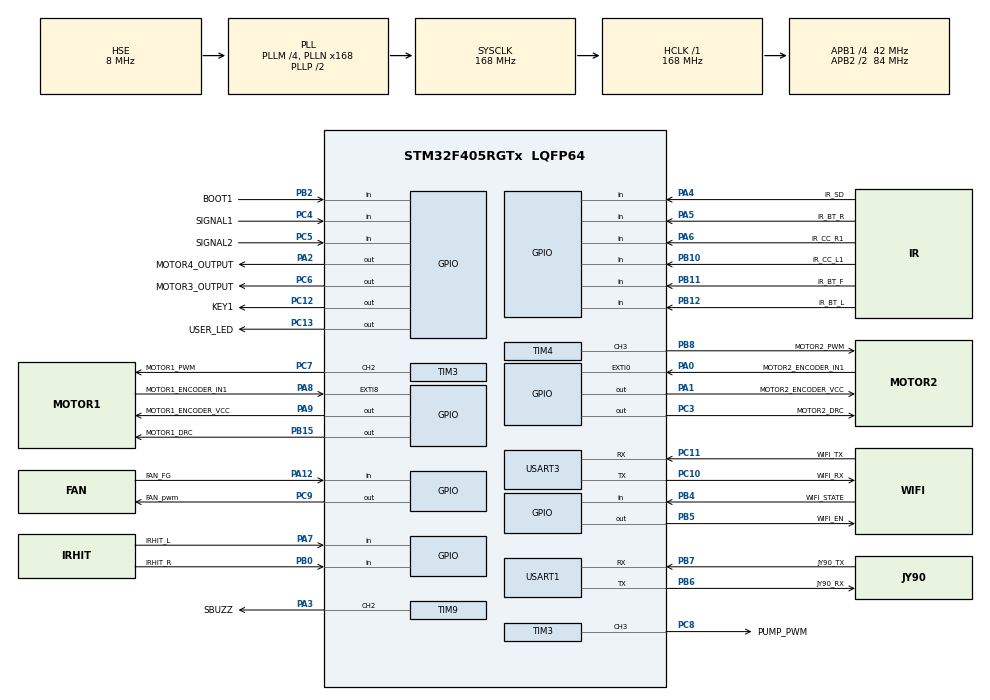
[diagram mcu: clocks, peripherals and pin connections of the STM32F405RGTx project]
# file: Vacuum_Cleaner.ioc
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FREERTOS.Tasks01=defaultTask,24,128,StartDefaultTask,Default,NULL,Dynamic,NULL,NULL
Mcu.Family=STM32F4
Mcu.Name=STM32F405RGTx
Mcu.Package=LQFP64
NVIC.EXTI0_IRQn=true\:5\:0\:false\:false\:true\:true\:true\:true\:true
NVIC.EXTI9_5_IRQn=true\:5\:0\:false\:false\:true\:true\:true\:true\:true
NVIC.PriorityGroup=NVIC_PRIORITYGROUP_4
NVIC.TIM1_UP_TIM10_IRQn=true\:5\:0\:false\:false\:true\:true\:true\:true\:true
NVIC.TIM2_IRQn=true\:5\:0\:false\:false\:true\:true\:true\:true\:true
NVIC.TIM5_IRQn=true\:15\:0\:false\:false\:true\:false\:false\:true\:true
NVIC.TimeBase=TIM5_IRQn
NVIC.TimeBaseIP=TIM5
NVIC.USART1_IRQn=true\:5\:0\:false\:false\:true\:true\:true\:true\:true
NVIC.USART3_IRQn=true\:5\:0\:false\:false\:true\:true\:true\:true\:true
PA0-WKUP.GPIO_Label=MOTOR2_ENCODER_IN1
PA0-WKUP.GPIO_PuPd=GPIO_PULLDOWN
PA0-WKUP.Signal=GPXTI0
PA1.GPIO_Label=MOTOR2_ENCODER_VCC
PA1.PinState=GPIO_PIN_SET
PA1.Signal=GPIO_Output
PA12.GPIO_Label=FAN_FG
PA12.Signal=GPIO_Input
PA13.Mode=Serial_Wire
PA13.Signal=SYS_JTMS-SWDIO
PA14.Mode=Serial_Wire
PA14.Signal=SYS_JTCK-SWCLK
PA2.GPIO_Label=MOTOR4_OUTPUT
PA2.PinState=GPIO_PIN_SET
PA2.Signal=GPIO_Output
PA3.GPIO_Label=SBUZZ
PA3.Signal=S_TIM9_CH2
PA4.GPIO_Label=IR_SD
PA4.Signal=GPIO_Input
PA5.GPIO_Label=IR_BT_R
PA5.Signal=GPIO_Input
PA6.GPIO_Label=IR_CC_R1
PA6.Signal=GPIO_Input
PA7.GPIO_Label=IRHIT_L
PA7.Signal=GPIO_Input
PA8.GPIO_Label=MOTOR1_ENCODER_IN1
PA8.GPIO_PuPd=GPIO_PULLDOWN
PA8.Signal=GPXTI8
PA9.GPIO_Label=MOTOR1_ENCODER_VCC
PA9.PinState=GPIO_PIN_SET
PA9.Signal=GPIO_Output
PB0.GPIO_Label=IRHIT_R
PB0.Signal=GPIO_Input
PB10.GPIO_Label=IR_CC_L1
PB10.Signal=GPIO_Input
PB11.GPIO_Label=IR_BT_F
PB11.Signal=GPIO_Input
PB12.GPIO_Label=IR_BT_L
PB12.Signal=GPIO_Input
PB15.GPIO_Label=MOTOR1_DRC
PB15.PinState=GPIO_PIN_SET
PB15.Signal=GPIO_Output
PB2.GPIO_Label=BOOT1
PB2.Signal=GPIO_Input
PB4.GPIO_Label=WIFI_STATE
PB4.Signal=GPIO_Input
PB5.GPIO_Label=WIFI_EN
PB5.PinState=GPIO_PIN_SET
PB5.Signal=GPIO_Output
PB6.GPIO_Label=JY90_RX
PB6.Mode=Asynchronous
PB6.Signal=USART1_TX
PB7.GPIO_Label=JY90_TX
PB7.Mode=Asynchronous
PB7.Signal=USART1_RX
PB8.GPIO_Label=MOTOR2_PWM
PB8.Signal=S_TIM4_CH3
PC10.GPIO_Label=WIFI_RX
PC10.Mode=Asynchronous
PC10.Signal=USART3_TX
PC11.GPIO_Label=WIFI_TX
PC11.Mode=Asynchronous
PC11.Signal=USART3_RX
PC12.GPIO_Label=KEY1
PC12.Signal=GPIO_Output
PC13-ANTI_TAMP.GPIO_Label=USER_LED
PC13-ANTI_TAMP.PinState=GPIO_PIN_RESET
PC13-ANTI_TAMP.Signal=GPIO_Output
PC14-OSC32_IN.Mode=LSE-External-Oscillator
PC14-OSC32_IN.Signal=RCC_OSC32_IN
PC15-OSC32_OUT.Mode=LSE-External-Oscillator
PC15-OSC32_OUT.Signal=RCC_OSC32_OUT
PC3.GPIO_Label=MOTOR2_DRC
PC3.PinState=GPIO_PIN_RESET
PC3.Signal=GPIO_Output
PC4.GPIO_Label=SIGNAL1
PC4.Signal=GPIO_Input
PC5.GPIO_Label=SIGNAL2
PC5.Signal=GPIO_Input
PC6.GPIO_Label=MOTOR3_OUTPUT
PC6.PinState=GPIO_PIN_RESET
PC6.Signal=GPIO_Output
PC7.GPIO_Label=MOTOR1_PWM
PC7.Signal=S_TIM3_CH2
PC8.GPIO_Label=PUMP_PWM
PC8.Signal=S_TIM3_CH3
PC9.GPIO_Label=FAN_pwm
PC9.PinState=GPIO_PIN_RESET
PC9.Signal=GPIO_Output
PH0-OSC_IN.Mode=HSE-External-Oscillator
PH0-OSC_IN.Signal=RCC_OSC_IN
PH1-OSC_OUT.Mode=HSE-External-Oscillator
PH1-OSC_OUT.Signal=RCC_OSC_OUT
ProjectManager.HeapSize=0x200
ProjectManager.StackSize=0x400
ProjectManager.TargetToolchain=Makefile
RCC.48MHZClocksFreq_Value=84000000
RCC.AHBFreq_Value=168000000
RCC.APB1CLKDivider=RCC_HCLK_DIV4
RCC.APB1Freq_Value=42000000
RCC.APB1TimFreq_Value=84000000
RCC.APB2CLKDivider=RCC_HCLK_DIV2
RCC.APB2Freq_Value=84000000
RCC.APB2TimFreq_Value=168000000
RCC.CortexFreq_Value=168000000
RCC.HCLKFreq_Value=168000000
RCC.HSE_VALUE=8000000
RCC.HSI_VALUE=16000000
RCC.PLLM=4
RCC.PLLN=168
RCC.PLLSourceVirtual=RCC_PLLSOURCE_HSE
RCC.SYSCLKFreq_VALUE=168000000
RCC.SYSCLKSource=RCC_SYSCLKSOURCE_PLLCLK
RCC.VCOOutputFreq_Value=336000000
SH.S_TIM3_CH2.0=TIM3_CH2,PWM Generation2 CH2
SH.S_TIM3_CH3.0=TIM3_CH3,PWM Generation3 CH3
SH.S_TIM4_CH3.0=TIM4_CH3,PWM Generation3 CH3
SH.S_TIM9_CH2.0=TIM9_CH2,PWM Generation2 CH2
STMicroelectronics.X-CUBE-ALGOBUILD.1.4.0.LibraryCcDSPOoLibraryJjDSPOoLibrary=true
TIM1.Period=5000-1
TIM1.Prescaler=167
TIM2.Period=5000-1
TIM2.Prescaler=83
TIM3.Channel-PWM\ Generation2\ CH2=TIM_CHANNEL_2
TIM3.Channel-PWM\ Generation3\ CH3=TIM_CHANNEL_3
TIM3.OCPolarity_2=TIM_OCPOLARITY_HIGH
TIM3.Period=99
TIM3.Prescaler=84-1
TIM3.Pulse-PWM\ Generation2\ CH2=90
TIM4.Channel-PWM\ Generation3\ CH3=TIM_CHANNEL_3
TIM4.Channel-PWM\ Generation4\ CH4=TIM_CHANNEL_4
TIM4.Period=99
TIM4.Prescaler=84-1
TIM4.Pulse-PWM\ Generation3\ CH3=10
TIM9.Channel-PWM\ Generation2\ CH2=TIM_CHANNEL_2
USART1.VirtualMode=VM_ASYNC
USART3.VirtualMode=VM_ASYNC
VP_FREERTOS_VS_CMSIS_V2.Mode=CMSIS_V2
VP_STMicroelectronics.X-CUBE-ALGOBUILD_VS_DSPOoLibraryJjLibrary_1.4.0_1.4.0.Mode=DSPOoLibraryJjLibrary
VP_SYS_VS_tim5.Mode=TIM5
VP_TIM1_VS_ClockSourceINT.Mode=Internal
VP_TIM2_VS_ClockSourceINT.Mode=Internal
board=custom

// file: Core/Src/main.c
/* USER CODE BEGIN Header */
/**
 ******************************************************************************
 * @file           : main.c
 * @brief          : Main program body
 ******************************************************************************
 * @attention
 *
 * Copyright (c) 2025 STMicroelectronics.
 * All rights reserved.
 *
 * This software is licensed under terms that can be found in the LICENSE file
 * in the root directory of this software component.
 * If no LICENSE file comes with this software, it is provided AS-IS.
 *
 ******************************************************************************
 */
/* USER CODE END Header */
#include "main.h"
#include "cmsis_os.h"
#include "tim.h"
#include "usart.h"
#include "gpio.h"

/* USER CODE BEGIN Includes */
// #include "JY901S.h"
#include "NJY901S.h"
#include "stdio.h"

/* USER CODE END Includes */

void SystemClock_Config(void);
void MX_FREERTOS_Init(void);

/* USER CODE BEGIN 0 */
int __io_putchar(int ch)
{
    HAL_UART_Transmit(&huart3, (uint8_t *)&ch, 1, HAL_MAX_DELAY);
    return ch;
}

/* USER CODE END 0 */

int main(void)
{

  /* MCU Configuration--------------------------------------------------------*/

  /* Reset of all peripherals, Initializes the Flash interface and the Systick. */
  HAL_Init();

  /* Configure the system clock */
  SystemClock_Config();

  /* Initialize all configured peripherals */
  MX_GPIO_Init();
  MX_TIM3_Init();
  MX_TIM4_Init();
  MX_TIM9_Init();
  MX_USART1_UART_Init();
  MX_USART3_UART_Init();
  MX_TIM1_Init();
  MX_TIM2_Init();
  /* USER CODE BEGIN 2 */
  // HAL_TIM_PWM_Start_IT(&htim4, TIM_CHANNEL_3);

  /* USER CODE END 2 */

  /* Init scheduler */
  osKernelInitialize();

  /* Call init function for freertos objects (in cmsis_os2.c) */
  MX_FREERTOS_Init();

  /* Start scheduler */
  osKernelStart();

  /* We should never get here as control is now taken by the scheduler */

  /* Infinite loop */
  while (1)
  {

  }
}

void SystemClock_Config(void)
{
  RCC_OscInitTypeDef RCC_OscInitStruct = {0};
  RCC_ClkInitTypeDef RCC_ClkInitStruct = {0};

  /** Configure the main internal regulator output voltage
  */
  __HAL_RCC_PWR_CLK_ENABLE();
  __HAL_PWR_VOLTAGESCALING_CONFIG(PWR_REGULATOR_VOLTAGE_SCALE1);

  /** Initializes the RCC Oscillators according to the specified parameters
  * in the RCC_OscInitTypeDef structure.
  */
  RCC_OscInitStruct.OscillatorType = RCC_OSCILLATORTYPE_HSE;
  RCC_OscInitStruct.HSEState = RCC_HSE_ON;
  RCC_OscInitStruct.PLL.PLLState = RCC_PLL_ON;
  RCC_OscInitStruct.PLL.PLLSource = RCC_PLLSOURCE_HSE;
  RCC_OscInitStruct.PLL.PLLM = 4;
  RCC_OscInitStruct.PLL.PLLN = 168;
  RCC_OscInitStruct.PLL.PLLP = RCC_PLLP_DIV2;
  RCC_OscInitStruct.PLL.PLLQ = 4;
  if (HAL_RCC_OscConfig(&RCC_OscInitStruct) != HAL_OK)
  {
    Error_Handler();
  }

  /** Initializes the CPU, AHB and APB buses clocks
  */
  RCC_ClkInitStruct.ClockType = RCC_CLOCKTYPE_HCLK|RCC_CLOCKTYPE_SYSCLK
                              |RCC_CLOCKTYPE_PCLK1|RCC_CLOCKTYPE_PCLK2;
  RCC_ClkInitStruct.SYSCLKSource = RCC_SYSCLKSOURCE_PLLCLK;
  RCC_ClkInitStruct.AHBCLKDivider = RCC_SYSCLK_DIV1;
  RCC_ClkInitStruct.APB1CLKDivider = RCC_HCLK_DIV4;
  RCC_ClkInitStruct.APB2CLKDivider = RCC_HCLK_DIV2;

  if (HAL_RCC_ClockConfig(&RCC_ClkInitStruct, FLASH_LATENCY_5) != HAL_OK)
  {
    Error_Handler();
  }
}

// void HAL_TIM_PeriodElapsedCallback(TIM_HandleTypeDef *htim)
// {
//   /* USER CODE BEGIN Callback 0 */

//   /* USER CODE END Callback 0 */
//   if (htim->Instance == TIM5)
//   {
//     HAL_IncTick();
//   }
//   /* USER CODE BEGIN Callback 1 */

//   /* USER CODE END Callback 1 */
// }

void Error_Handler(void)
{
  __disable_irq();
  while (1)
  {
  }
}

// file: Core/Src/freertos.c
/* USER CODE BEGIN Header */
/**
  ******************************************************************************
  * File Name          : freertos.c
  * Description        : Code for freertos applications
  ******************************************************************************
  * @attention
  *
  * Copyright (c) 2025 STMicroelectronics.
  * All rights reserved.
  *
  * This software is licensed under terms that can be found in the LICENSE file
  * in the root directory of this software component.
  * If no LICENSE file comes with this software, it is provided AS-IS.
  *
  ******************************************************************************
  */
/* USER CODE END Header */

#include "FreeRTOS.h"
#include "task.h"
#include "main.h"
#include "cmsis_os.h"

/* USER CODE BEGIN Includes */
#include "robot_task.h"
/* USER CODE END Includes */

/* Definitions for defaultTask */
osThreadId_t defaultTaskHandle;
const osThreadAttr_t defaultTask_attributes = {
  .name = "defaultTask",
  .stack_size = 128 * 4,
  .priority = (osPriority_t) osPriorityNormal,
};

void StartDefaultTask(void *argument);

void MX_FREERTOS_Init(void); /* (MISRA C 2004 rule 8.1) */

void MX_FREERTOS_Init(void) {

  /* Create the thread(s) */
  /* creation of defaultTask */
  defaultTaskHandle = osThreadNew(StartDefaultTask, NULL, &defaultTask_attributes);

  /* USER CODE BEGIN RTOS_THREADS */
  /* add threads, ... */
  OSTaskInit();
  /* USER CODE END RTOS_THREADS */

}

void StartDefaultTask(void *argument)
{
  for(;;)
  {
    osDelay(1);
  }
}
